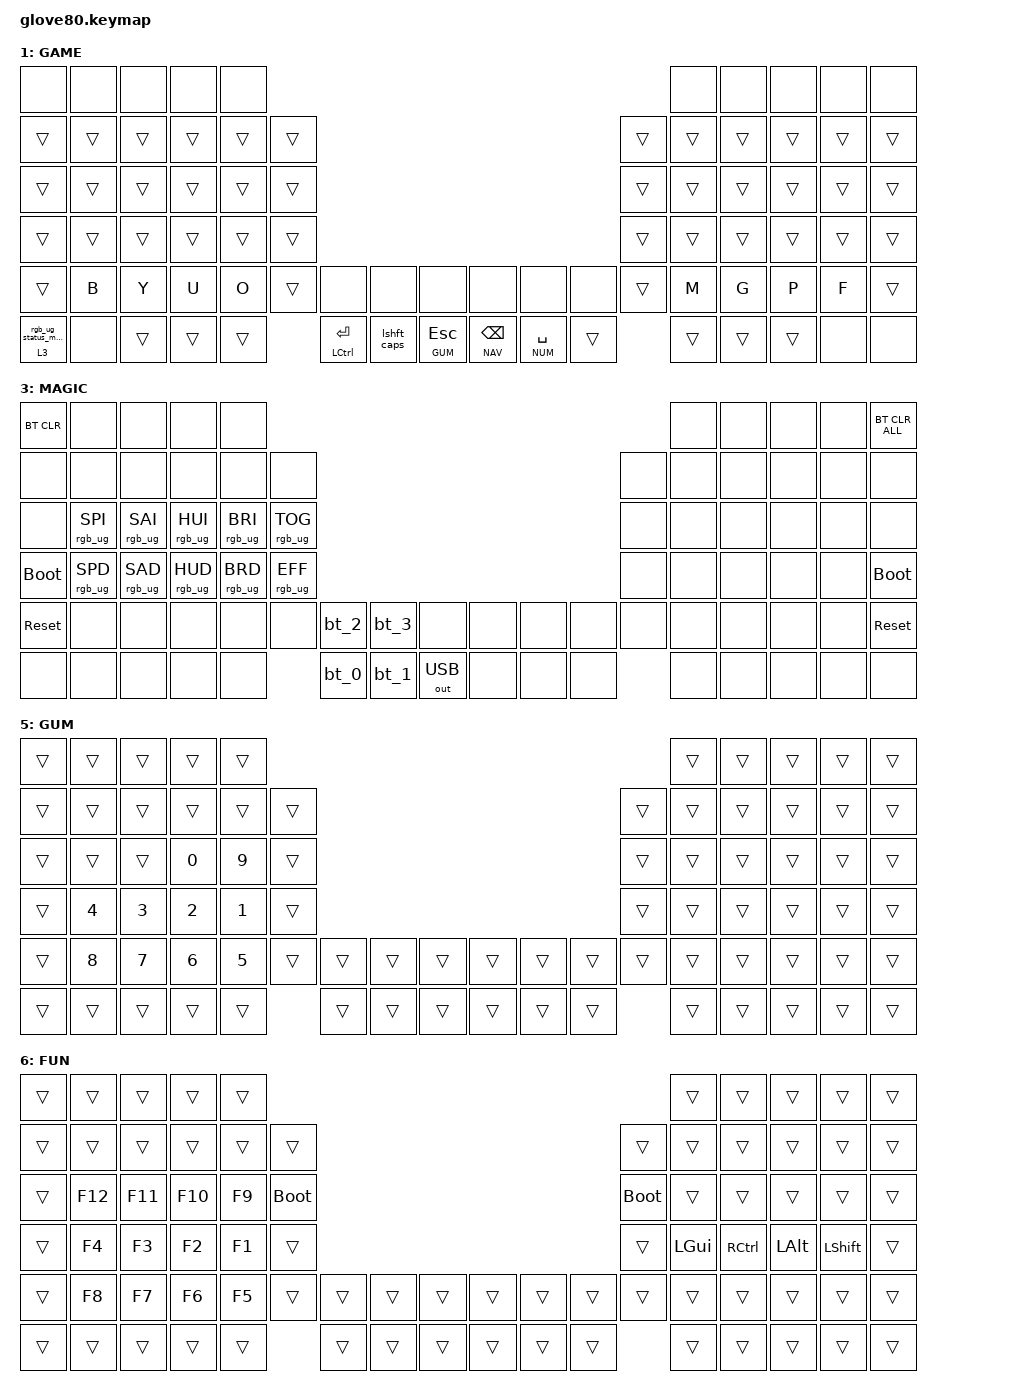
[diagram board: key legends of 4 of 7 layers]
/*
 * Copyright (c) 2020 The ZMK Contributors
 * Copyright (c) 2023 Innaworks Development Limited, trading as MoErgo
 *
 * SPDX-License-Identifier: MIT
 */


#include <behaviors.dtsi>
/* Include all behaviour includes needed */
#include <dt-bindings/zmk/outputs.h>
#include <dt-bindings/zmk/keys.h>
#include <dt-bindings/zmk/bt.h>
#include <dt-bindings/zmk/rgb.h>

/* To deal with the situation where there is no Lower layer, to keep &lower happy */
#ifndef LAYER_Lower
#define LAYER_Lower 0
#endif

/ {
    /* Glove80 system behavior & macros */
    behaviors {
        // For the "layer" key, it'd nice to be able to use it as either a shift or a toggle.
        // Configure it as a tap dance, so the first tap (or hold) is a &mo and the second tap is a &to
        lower: lower {
            compatible = "zmk,behavior-tap-dance";
            label = "LAYER_TAP_DANCE";
            #binding-cells = <0>;
            tapping-term-ms = <200>;
            bindings = <&mo LAYER_Lower>, <&to LAYER_Lower>;
        };
    };
};

/ {
    macros {
        rgb_ug_status_macro: rgb_ug_status_macro {
            label = "RGB_UG_STATUS";
            compatible = "zmk,behavior-macro";
            #binding-cells = <0>;
            bindings
                = <&rgb_ug RGB_STATUS>;
        };

        bt_0: bt_0 {
            label = "BT_0";
            compatible = "zmk,behavior-macro";
            #binding-cells = <0>;
            bindings
                = <&out OUT_BLE>,
                  <&bt BT_SEL 0>;
        };

        bt_1: bt_1 {
            label = "BT_1";
            compatible = "zmk,behavior-macro";
            #binding-cells = <0>;
            bindings
                = <&out OUT_BLE>,
                  <&bt BT_SEL 1>;
        };

        bt_2: bt_2 {
            label = "BT_2";
            compatible = "zmk,behavior-macro";
            #binding-cells = <0>;
            bindings
                = <&out OUT_BLE>,
                  <&bt BT_SEL 2>;
        };

        bt_3: bt_3 {
            label = "BT_3";
            compatible = "zmk,behavior-macro";
            #binding-cells = <0>;
            bindings
                = <&out OUT_BLE>,
                  <&bt BT_SEL 3>;
        };
    };
};

/ {
    magic: magic {
        compatible = "zmk,behavior-hold-tap";
        label = "MAGIC_HOLD_TAP";
        #binding-cells = <2>;
        flavor = "tap-preferred";
        tapping-term-ms = <200>;
        bindings = <&mo>, <&rgb_ug_status_macro>;
    };
};

    /* #define for key positions */
#define POS_LH_T1 52
#define POS_LH_T2 53
#define POS_LH_T3 54
#define POS_LH_T4 69
#define POS_LH_T5 70
#define POS_LH_T6 71
#define POS_LH_C1R2 15
#define POS_LH_C1R3 27
#define POS_LH_C1R4 39
#define POS_LH_C1R5 51
#define POS_LH_C2R1 4
#define POS_LH_C2R2 14
#define POS_LH_C2R3 26
#define POS_LH_C2R4 38
#define POS_LH_C2R5 50
#define POS_LH_C2R6 68
#define POS_LH_C3R1 3
#define POS_LH_C3R2 13
#define POS_LH_C3R3 25
#define POS_LH_C3R4 37
#define POS_LH_C3R5 49
#define POS_LH_C3R6 67
#define POS_LH_C4R1 2
#define POS_LH_C4R2 12
#define POS_LH_C4R3 24
#define POS_LH_C4R4 36
#define POS_LH_C4R5 48
#define POS_LH_C4R6 66
#define POS_LH_C5R1 1
#define POS_LH_C5R2 11
#define POS_LH_C5R3 23
#define POS_LH_C5R4 35
#define POS_LH_C5R5 47
#define POS_LH_C5R6 65
#define POS_LH_C6R1 0
#define POS_LH_C6R2 10
#define POS_LH_C6R3 22
#define POS_LH_C6R4 34
#define POS_LH_C6R5 46
#define POS_LH_C6R6 64
#define POS_RH_T1 57
#define POS_RH_T2 56
#define POS_RH_T3 55
#define POS_RH_T4 74
#define POS_RH_T5 73
#define POS_RH_T6 72
#define POS_RH_C1R2 16
#define POS_RH_C1R3 28
#define POS_RH_C1R4 40
#define POS_RH_C1R5 58
#define POS_RH_C2R1 5
#define POS_RH_C2R2 17
#define POS_RH_C2R3 29
#define POS_RH_C2R4 41
#define POS_RH_C2R5 59
#define POS_RH_C2R6 75
#define POS_RH_C3R1 6
#define POS_RH_C3R2 18
#define POS_RH_C3R3 30
#define POS_RH_C3R4 42
#define POS_RH_C3R5 60
#define POS_RH_C3R6 76
#define POS_RH_C4R1 7
#define POS_RH_C4R2 19
#define POS_RH_C4R3 31
#define POS_RH_C4R4 43
#define POS_RH_C4R5 61
#define POS_RH_C4R6 77
#define POS_RH_C5R1 8
#define POS_RH_C5R2 20
#define POS_RH_C5R3 32
#define POS_RH_C5R4 44
#define POS_RH_C5R5 62
#define POS_RH_C5R6 78
#define POS_RH_C6R1 9
#define POS_RH_C6R2 21
#define POS_RH_C6R3 33
#define POS_RH_C6R4 45
#define POS_RH_C6R5 63
#define POS_RH_C6R6 79

    /* Custom Defined Behaviors */
/ {
    /* How long Sticky Keys and Sticky Layers stay pressed */
#define STICKY_KEY_RELEASE_AFTER_MS 600

/* How quickly Combo keys must be pressed together */
#define COMBO_TIMEOUT_MS 45

/* How quickly both thumb Shift keys must be pressed together to activate Caps
   Word */
#define CAPS_WORD_COMBO_TIMEOUT_MS 150

/* How long to hold to activate home row mods for same side or mouse usage */
#define HOME_ROW_MODS_TAPPING_TERM_MS 300

/* Cool down after typing before home row mods can be used */
#define HOME_ROW_MODS_QUICK_TAP_MS 250

/* How long thumb keys can be held before rolls send the higher layer key */
#define THUMBS_TAPPING_TERM_MS 200

/* How quickly to double tap reaching thumb keys to hold down the tap action */
#define REACH_THUMBS_QUICK_TAP_MS 250

/* How long until each phase of the typing assist features times out */
#define TYPING_ASSIST_TIMEOUT_MS 60000

/* How long to hold for Autoshift */
#define AUTOSHIFT_TAPPING_TERM_MS 200

/* How long until the word and line selection feature times out */
#define SELECT_TIMEOUT_MS 60000

/* How quickly confirmation action keys must be double tapped to activate */
#define DOUBLE_TAP_TIMEOUT_MS 250

/* Set layer names */
#define BASE 0
#define GAME 1
#define NAV 2
#define MAGIC 3
#define NUM 4
#define GUM 5
#define FUN 6


/* Convert NAME parameters into a ZMK label string */
#define STRINGIFY(x) #x

/* Create a ZMK Behavior without having to specify the name three times */
#define ZMK_BEHAVIOR(NAME, ...) \
    behaviors { \
        NAME: NAME { \
            label = STRINGIFY(ZB_ ## NAME); \
            __VA_ARGS__ \
        }; \
    };

/* Hold-Tap helper */
#define HOLD_TAP(NAME, ...) \
    ZMK_BEHAVIOR(NAME, \
        compatible = "zmk,behavior-hold-tap"; \
        #binding-cells = <2>; \
        __VA_ARGS__ \
    )

/* Balanced Hold-Tap for home row mods and thumb layer keys */
#define BALANCED_HOLD_TAP(NAME, ...) \
    HOLD_TAP(NAME, \
        flavor = "balanced";  /* Fast hold */ \
        __VA_ARGS__ \
    )


behaviors {

    /* Let Caps Word continue when typing Underscore */
    behavior_caps_word {
        continue-list = <UNDERSCORE MINUS BACKSPACE DELETE>;
    };

    /* Use defined timer for Sticky Keys */
    behavior_sticky_key {
        release-after-ms = <STICKY_KEY_RELEASE_AFTER_MS>;
        quick-release;
    };

    /* Use defined timer for Sticky Layers */
    behavior_sticky_layer {
        release-after-ms = <STICKY_KEY_RELEASE_AFTER_MS>;
    };

};

/* "Timerless" home row mod Hold-Tap using defined timers */
#define HOME_ROW_MOD_HELPER(NAME, KEY_POSITIONS, TAP) \
    BALANCED_HOLD_TAP(NAME, \
        tapping-term-ms = <HOME_ROW_MODS_TAPPING_TERM_MS>;  /* Mouse usage */ \
        quick-tap-ms = <HOME_ROW_MODS_QUICK_TAP_MS>;  /* Typing cool down */ \
        require-prior-idle-ms = <150>; \
        hold-trigger-key-positions = <KEY_POSITIONS>;  /* Use other hand */ \
        hold-trigger-on-release; \
        bindings = <&kp>, <TAP>; \
    )

/* Left hand key positions for use with right hand mods */
#define LEFT_HAND_KEYS \
    /*    ┌────┬────┬────┬────┬────┐                                       */ \
             0    1    2    3    4                                            \
    /*    ├────┼────┼────┼────┼────┼────┐                                  */ \
            10   11   12   13   14   15                                       \
    /*    ├────┼────┼────┼────┼────┼────┤                                  */ \
            22   23   24   25   26   27                                       \
    /*    ├────┼────┼────┼────┼────┼────┤                                  */ \
            34   35   36   37   38   39                                       \
    /*    ├────┼────┼────┼────┼────┼────┤                                  */ \
            46   47   48   49   50   51                                       \
    /*    ├────┼────┼────┼────┼────┼────┘                                  */ \
            64   65   66   67   68
    /*    └────┴────┴────┴────┴────┘                                       */

/* Right hand key positions for use with left hand mods */
#define RIGHT_HAND_KEYS \
    /*                                          ┌────┬────┬────┬────┬────┐ */ \
                                                   5    6    7    8    9      \
    /*                                     ┌────┼────┼────┼────┼────┼────┤ */ \
                                             16   17   18   19   20   21      \
    /*                                     ├────┼────┼────┼────┼────┼────┤ */ \
                                             28   29   30   31   32   33      \
    /*                                     ├────┼────┼────┼────┼────┼────┤ */ \
                                             40   41   42   43   44   45      \
    /*                                     ├────┼────┼────┼────┼────┼────┤ */ \
                                             58   59   60   61   62   63      \
    /*                                     └────┼────┼────┼────┼────┼────┤ */ \
                                                  75   76   77   78   79
    /*                                          └────┴────┴────┴────┴────┘ */

/* Thumb key positions for use with mods on both hands */
#define THUMB_KEYS \
    /*                 ┌────┬────┬────┐      ┌────┬────┬────┐              */ \
                         52   53   54          55   56   57                   \
    /*                 ├────┼────┼────┤      ├────┼────┼────┤              */ \
                         69   70   71          72   73   74
    /*                 └────┴────┴────┘      └────┴────┴────┘              */ 


/* Left and right hand home row mods */
#define HOME_ROW_MOD_LH(NAME, TAP) \
    HOME_ROW_MOD_HELPER(NAME, RIGHT_HAND_KEYS THUMB_KEYS, TAP)
#define HOME_ROW_MOD_RH(NAME, TAP) \
    HOME_ROW_MOD_HELPER(NAME, LEFT_HAND_KEYS THUMB_KEYS, TAP)

HOME_ROW_MOD_LH(lh_hr_mt, &kp)  /* Left hand */
HOME_ROW_MOD_RH(rh_hr_mt, &kp)  /* Right hand */


/* Home thumb layer tap without quick tap; faster layer switching */
#define HOME_THUMB_LAYER_TAP(NAME, TAP_BINDING) \
    BALANCED_HOLD_TAP(NAME, \
        tapping-term-ms = <THUMBS_TAPPING_TERM_MS>;  /* Rolls send tap key */ \
        bindings = <&mo>, <TAP_BINDING>; \
    )

/* Reaching thumb layer tap with double tap to repeat */
#define REACH_THUMB_LAYER_TAP(NAME, TAP_BINDING) \
    BALANCED_HOLD_TAP(NAME, \
        tapping-term-ms = <THUMBS_TAPPING_TERM_MS>;  /* Rolls send tap key */ \
        quick-tap-ms = <REACH_THUMBS_QUICK_TAP_MS>;  /* Double tap repeats */ \
        bindings = <&mo>, <TAP_BINDING>; \
    )

HOME_THUMB_LAYER_TAP(ht_lt, &kp)  /* Used for Editing and Numbers layers */
REACH_THUMB_LAYER_TAP(rt_lt, &kp)  /* Used for Media and Function layers */


/* Mod-Morph helper */
#define MOD_MORPH(NAME, STANDARD, MORPHED, MODS, ...) \
    ZMK_BEHAVIOR(NAME, \
        compatible = "zmk,behavior-mod-morph"; \
        #binding-cells = <0>; \
        bindings = <STANDARD>, <MORPHED>; \
        mods = <(MODS)>; \
        __VA_ARGS__ \
    )

MOD_MORPH(lshft_caps, &sk LSHFT, &caps_word, MOD_LSFT)
MOD_MORPH(dot_col, &kp DOT, &kp LS(SEMI), MOD_LSFT)
MOD_MORPH(com_sem, &kp COMMA, &kp SEMI, MOD_LSFT)
MOD_MORPH(quebng, &kp QUESTION, &kp EXCLAMATION, MOD_LSFT)
MOD_MORPH(slashy, &kp SLASH, &kp BACKSLASH, MOD_LSFT)


/* Combo helper */
#define ZMK_COMBO(NAME, TIMEOUT_MS, KEY_POSITIONS, BINDINGS) \
    NAME { \
        require-prior-idle-ms = <100>; \
        timeout-ms = <TIMEOUT_MS>; \
        key-positions = <KEY_POSITIONS>; \
        bindings = <BINDINGS>; \
    };

/* Use defined timer for most Combos */
#define COMBO(NAME, KEY_POSITIONS, BINDINGS) \
    ZMK_COMBO(NAME, COMBO_TIMEOUT_MS, KEY_POSITIONS, BINDINGS)

combos {
    compatible = "zmk,combos";

    /* COMBO(combo_dash, 49 50, &kp MINUS) */
    /* COMBO(combo_underscore, 48 49, &kp UNDERSCORE) */
    /* COMBO(combo_slash, 42 60, &kp SLASH) */
    /* COMBO(combo_backslash, 43 61, &kp BACKSLASH) */
    COMBO(combo_esc, 48 49, &kp ESC)
    COMBO(combo_tab, 59 60, &kp TAB)
    COMBO(combo_ret, 60 61, &kp ENTER)
    /* COMBO(combo_equal, 60 61, &kp EQUAL) */
    /* COMBO(combo_lparen, 38 50, &kp LEFT_PARENTHESIS) */
    /* COMBO(combo_lbracket, 37 49, &kp LEFT_BRACKET) */
    /* COMBO(combo_lbrace, 36 48, &kp LEFT_BRACE) */
    /* COMBO(combo_rparen, 26 38, &kp RIGHT_PARENTHESIS) */
    /* COMBO(combo_rbracket, 25 37, &kp RIGHT_BRACKET) */
    /* COMBO(combo_rbrace, 24 36, &kp RIGHT_BRACE) */
};

};

#define PTAB &kp LC(LS(TAB))
#define NTAB &kp LC(TAB)

#define VOLU &kp C_VOL_UP
#define VOLD &kp C_VOL_DN

#define HRML(k1,k2,k3,k4) &lh_hr_mt LSHFT k1 &lh_hr_mt LALT k2 &lh_hr_mt LCTRL k3 &lh_hr_mt LGUI k4
#define HRMR(k1,k2,k3,k4) &rh_hr_mt LGUI k1 &rh_hr_mt LCTRL k2 &rh_hr_mt LALT k3 &rh_hr_mt LSHFT k4

#define LSFT_C &lh_hr_mt LSHFT C
#define LALT_I &lh_hr_mt LALT I
#define LCTL_E &lh_hr_mt LCTRL E
#define LGUI_A &lh_hr_mt LGUI A
#define LGUI_H &rh_hr_mt LGUI H
#define RCTL_T &rh_hr_mt RCTRL T
#define LALT_N &rh_hr_mt LALT N
#define LSFT_S &rh_hr_mt LSHFT S

#define CS_DOT &lh_hr_mt LC(LSHFT) DOT
#define CS_C &rh_hr_mt LC(LSHFT) C
#define GS_P &lh_hr_mt LG(LSHFT) P
#define GS_G &rh_hr_mt LG(LSHFT) G

#define NAVTAB &ht_lt NAV TAB
#define NAVESC &ht_lt NAV ESC
#define NAVBSP &ht_lt NAV BSPC
#define NAVRET &ht_lt NAV ENTER
#define NUMESC &ht_lt NUM ESC
#define GUMESC &ht_lt GUM ESC
#define FUNBSP &rt_lt FUN BSPC
#define FUNRET &rt_lt FUN ENTER
#define FUNR &rt_lt FUN R
#define NUMSPC &ht_lt NUM SPACE
#define NUMBSPC &ht_lt NUM BSPC

/ {
    keymap {
        compatible = "zmk,keymap";


        BASE {
            bindings = <
&none      &none    &none      &none      &none                                                                       &none  &none    &none    &none  &none
&kp GRAVE  &kp N1   &kp N2     &kp N3     &kp N4   &kp N5                                                    &kp N6   &kp N7 &kp N8   &kp N9   &kp N0 &none
&kp TAB    &kp SQT  &kp X      &kp COMMA  &kp DOT  &kp EQUAL                                                 &kp BSLH &kp L  &kp D    &kp W    &kp V  &kp SLASH
&kp Q      &kp C    &kp I      &kp E      &kp A    &kp MINUS                                                 &kp K    &kp H  &kp T    &kp N    &kp S  &kp Z
&none      HRML(B,  Y,         U,         O)       &kp SEMI  &none  &none       &none   &none  &none  &none  &kp J    HRMR(M,G,       P,       F)     &none
&magic 3 0 &none    &kp LS(N9) &kp LS(N0) &none              NAVRET &lshft_caps NUMESC  FUNBSP NUMSPC &kp R           &none  &kp LBKT &kp RBKT &none  &none
            >;
        };

        GAME {
            bindings = <
&none      &none    &none     &none     &none                                                                                  &none  &none  &none  &none  &none
&trans     &trans   &trans    &trans    &trans   &trans                                                                &trans  &trans &trans &trans &trans &trans
&trans     &trans   &trans    &trans    &trans   &trans                                                                &trans  &trans &trans &trans &trans &trans
&trans     &trans   &trans    &trans    &trans   &trans                                                                &trans  &trans &trans &trans &trans &trans
&trans     &kp B    &kp Y     &kp U     &kp O    &trans       &none           &none       &none   &none  &none  &none  &trans  &kp M  &kp G  &kp P  &kp F  &trans
&magic 3 0 &none    &trans    &trans    &trans                &mt LCTRL ENTER &lshft_caps GUMESC  NAVBSP NUMSPC &trans         &trans &trans &trans &none  &none
            >;
        };

        NAV {
            bindings = <
&trans &trans      &trans     &trans    &trans                                                                         &trans   &trans    &trans    &trans    &trans
&trans &trans      &trans     &trans    &trans     &trans                                                       &trans &trans   &trans    &trans    &trans    &trans
&trans &none       VOLU       VOLD      &none      &none                                                        &trans PTAB     &none     &none     NTAB      &trans
&trans HRML(LC(C), LC(X),     LA(X),    LC(G))     &none                                                        &trans &kp LEFT &kp UP    &kp DOWN  &kp RIGHT &trans
&trans &kp C_PREV  &kp C_MUTE &kp C_PP  &kp C_NEXT &none     &trans  &trans  &trans  &trans   &trans  &trans    &trans &kp HOME &kp PG_UP &kp PG_DN &kp END   &trans
&trans &trans      &trans     &trans    &trans               &trans  &trans  &trans  &kp BSPC &trans  &tog GAME     &trans   &trans    &trans    &trans    &trans
            >;
        };

        MAGIC {
            bindings = <
&bt BT_CLR  &none           &none           &none           &none                                                                               &none &none &none &none &bt BT_CLR_ALL
&none       &none           &none           &none           &none           &none                                                         &none &none &none &none &none &none
&none       &rgb_ug RGB_SPI &rgb_ug RGB_SAI &rgb_ug RGB_HUI &rgb_ug RGB_BRI &rgb_ug RGB_TOG                                               &none &none &none &none &none &none
&bootloader &rgb_ug RGB_SPD &rgb_ug RGB_SAD &rgb_ug RGB_HUD &rgb_ug RGB_BRD &rgb_ug RGB_EFF                                               &none &none &none &none &none &bootloader
&sys_reset  &none           &none           &none           &none           &none           &bt_2   &bt_3  &none        &none &none &none &none &none &none &none &none &sys_reset
&none       &none           &none           &none           &none                           &bt_0   &bt_1  &out OUT_USB &none &none &none       &none &none &none &none &none
            >;
        };

        NUM {
            bindings = <
&trans &trans      &trans    &trans &trans                                                                     &trans       &trans        &trans       &trans     &trans
&trans &trans      &trans    &trans &trans &trans                                                    &trans    &trans       &trans        &trans       &trans     &trans
&trans &kp PERCENT &kp CARET &kp N0 &kp N9 &kp AMPS                                                  &trans    &trans       &kp LS(LBKT)  &kp LS(RBKT) &trans     &trans
&trans &kp N4      &kp N3    &kp N2 &kp N1 &kp DOLLAR                                                &trans    &kp LS(N9)   &kp LBKT      &kp RBKT     &kp LS(N0) &trans
&trans HRML(N8,    N7,       N6,    N5)    &kp HASH &trans    &trans  &trans    &trans &trans &trans &kp AT    HRMR(STAR,   LS(COMMA),    LS(DOT),     &trans)    &trans
&trans &trans      &trans    &trans &trans          &trans    &trans  &trans    &trans &trans &trans           &trans       &trans        &trans       &trans     &trans
            >;
        };

        GUM {
            bindings = <
&trans &trans      &trans    &trans &trans                                                                     &trans       &trans        &trans       &trans     &trans
&trans &trans      &trans    &trans &trans &trans                                                    &trans    &trans       &trans        &trans       &trans     &trans
&trans &trans      &trans    &kp N0 &kp N9 &trans                                                    &trans    &trans       &trans        &trans       &trans     &trans
&trans &kp N4      &kp N3    &kp N2 &kp N1 &trans                                                    &trans    &trans       &trans        &trans       &trans     &trans
&trans &kp N8      &kp N7    &kp N6 &kp N5 &trans   &trans    &trans  &trans    &trans &trans &trans &trans    &trans       &trans        &trans       &trans     &trans
&trans &trans      &trans    &trans &trans          &trans    &trans  &trans    &trans &trans &trans           &trans       &trans        &trans       &trans     &trans
            >;
        };

        FUN {
            bindings = <
&trans &trans  &trans  &trans  &trans                                                                   &trans   &trans    &trans   &trans    &trans
&trans &trans  &trans  &trans  &trans &trans                                                &trans      &trans   &trans    &trans   &trans    &trans
&trans &kp F12 &kp F11 &kp F10 &kp F9 &bootloader                                           &bootloader &trans   &trans    &trans   &trans    &trans
&trans &kp F4  &kp F3  &kp F2  &kp F1 &trans                                                &trans      &kp LGUI &kp RCTRL &kp LALT &kp LSHFT &trans
&trans &kp F8  &kp F7  &kp F6  &kp F5 &trans      &trans &trans &trans &trans &trans &trans &trans      &trans   &trans    &trans   &trans    &trans
&trans &trans  &trans  &trans  &trans             &trans &trans &trans &trans &trans &trans             &trans   &trans    &trans   &trans    &trans
            >;
        };

    };
};
